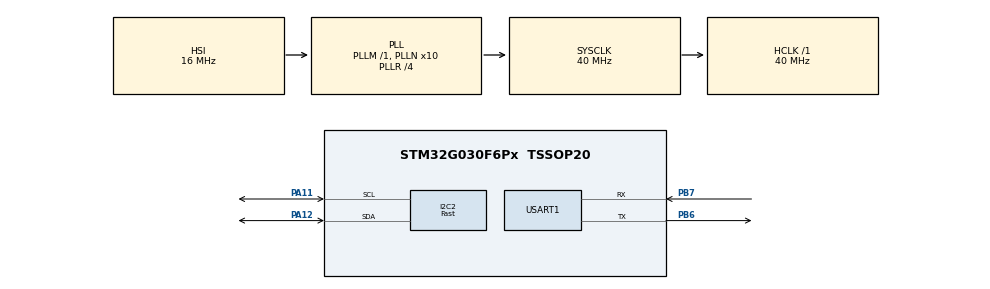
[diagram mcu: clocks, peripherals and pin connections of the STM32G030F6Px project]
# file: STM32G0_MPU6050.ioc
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I2C2.I2C_Speed_Mode=I2C_Fast
I2C2.Timing=0x00301347
Mcu.Family=STM32G0
Mcu.Name=STM32G030F6Px
Mcu.Package=TSSOP20
PA11\ [PA9].Mode=I2C
PA11\ [PA9].Signal=I2C2_SCL
PA12\ [PA10].Mode=I2C
PA12\ [PA10].Signal=I2C2_SDA
PA13.Mode=Serial_Wire
PA13.Signal=SYS_SWDIO
PA14-BOOT0.Mode=Serial_Wire
PA14-BOOT0.Signal=SYS_SWCLK
PA14-BOOT0__PA15.StandardMode=true
PB0__PB1__PB2__PA8.StandardMode=true
PB3__PB4__PB5__PB6.StandardMode=true
PB6.Mode=Asynchronous
PB6.Signal=USART1_TX
PB7.Mode=Asynchronous
PB7.Signal=USART1_RX
PB7__PB8.StandardMode=true
PC14-OSC32_IN\ (PC14)__PB9.StandardMode=true
ProjectManager.HeapSize=0x200
ProjectManager.StackSize=0x400
ProjectManager.TargetToolchain=MDK-ARM V5.32
RCC.ADCFreq_Value=40000000
RCC.AHBFreq_Value=40000000
RCC.CortexFreq_Value=40000000
RCC.EXTERNAL_CLOCK_VALUE=12288000
RCC.HCLKFreq_Value=40000000
RCC.HSE_VALUE=8000000
RCC.HSI_VALUE=16000000
RCC.LSE_VALUE=32768
RCC.PLLN=10
RCC.PLLR=RCC_PLLR_DIV4
RCC.SYSCLKFreq_VALUE=40000000
RCC.SYSCLKSource=RCC_SYSCLKSOURCE_PLLCLK
RCC.VCOOutputFreq_Value=160000000
USART1.VirtualMode-Asynchronous=VM_ASYNC
board=custom

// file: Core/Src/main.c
/* USER CODE BEGIN Header */
/*
 *  supports max 14 channels in this lib (with messagelength of 0x20 there is room for 14 channels)

  Example set of bytes coming over the iBUS line for setting servos:
    20 40 DB 5 DC 5 54 5 DC 5 E8 3 D0 7 D2 5 E8 3 DC 5 DC 5 DC 5 DC 5 DC 5 DC 5 DA F3
  Explanation
    Protocol length: 20
    Command code: 40
    Channel 0: DB 5  -> value 0x5DB
    Channel 1: DC 5  -> value 0x5Dc
    Channel 2: 54 5  -> value 0x554
    Channel 3: DC 5  -> value 0x5DC
    Channel 4: E8 3  -> value 0x3E8
    Channel 5: D0 7  -> value 0x7D0
    Channel 6: D2 5  -> value 0x5D2
    Channel 7: E8 3  -> value 0x3E8
    Channel 8: DC 5  -> value 0x5DC
    Channel 9: DC 5  -> value 0x5DC
    Channel 10: DC 5 -> value 0x5DC
    Channel 11: DC 5 -> value 0x5DC
    Channel 12: DC 5 -> value 0x5DC
    Channel 13: DC 5 -> value 0x5DC
    Checksum: DA F3 -> calculated by adding up all previous bytes, total must be FFFF
*/
/* USER CODE END Header */
#include "main.h"
#include "i2c.h"
#include "usart.h"
#include "gpio.h"

/* USER CODE BEGIN Includes */
#include "mpu6050.h"
/* USER CODE END Includes */

void SystemClock_Config(void);

int main(void)
{

  /* MCU Configuration--------------------------------------------------------*/

  /* Reset of all peripherals, Initializes the Flash interface and the Systick. */
  HAL_Init();

  /* Configure the system clock */
  SystemClock_Config();

  /* Initialize all configured peripherals */
  MX_GPIO_Init();
  MX_USART1_UART_Init();
  MX_I2C2_Init();
  /* USER CODE BEGIN 2 */
  printf("System Begin!\r\n");
  uint8_t addr = 0xff;
  addr = i2c_probe();
  printf("I2C Address: 0x%02x\r\n", addr);//0xD0
  mpu6050_init();
  /* USER CODE END 2 */

  /* Infinite loop */
  while (1)
  {

    /* USER CODE BEGIN 3 */
    uint16_t acc[3];
    mpu6050_read_only_acc(acc);
    printf("Acc: %f %f %f\r\n",
    mpu6050_from_fs2g_to_g(acc[0]),
    mpu6050_from_fs2g_to_g(acc[1]),
    mpu6050_from_fs2g_to_g(acc[2]));
    HAL_Delay(100);
  }
  /* USER CODE END 3 */
}

void SystemClock_Config(void)
{
  RCC_OscInitTypeDef RCC_OscInitStruct = {0};
  RCC_ClkInitTypeDef RCC_ClkInitStruct = {0};

  /** Configure the main internal regulator output voltage
  */
  HAL_PWREx_ControlVoltageScaling(PWR_REGULATOR_VOLTAGE_SCALE1);

  /** Initializes the RCC Oscillators according to the specified parameters
  * in the RCC_OscInitTypeDef structure.
  */
  RCC_OscInitStruct.OscillatorType = RCC_OSCILLATORTYPE_HSI;
  RCC_OscInitStruct.HSIState = RCC_HSI_ON;
  RCC_OscInitStruct.HSIDiv = RCC_HSI_DIV1;
  RCC_OscInitStruct.HSICalibrationValue = RCC_HSICALIBRATION_DEFAULT;
  RCC_OscInitStruct.PLL.PLLState = RCC_PLL_ON;
  RCC_OscInitStruct.PLL.PLLSource = RCC_PLLSOURCE_HSI;
  RCC_OscInitStruct.PLL.PLLM = RCC_PLLM_DIV1;
  RCC_OscInitStruct.PLL.PLLN = 10;
  RCC_OscInitStruct.PLL.PLLP = RCC_PLLP_DIV2;
  RCC_OscInitStruct.PLL.PLLR = RCC_PLLR_DIV4;
  if (HAL_RCC_OscConfig(&RCC_OscInitStruct) != HAL_OK)
  {
    Error_Handler();
  }

  /** Initializes the CPU, AHB and APB buses clocks
  */
  RCC_ClkInitStruct.ClockType = RCC_CLOCKTYPE_HCLK|RCC_CLOCKTYPE_SYSCLK
                              |RCC_CLOCKTYPE_PCLK1;
  RCC_ClkInitStruct.SYSCLKSource = RCC_SYSCLKSOURCE_PLLCLK;
  RCC_ClkInitStruct.AHBCLKDivider = RCC_SYSCLK_DIV1;
  RCC_ClkInitStruct.APB1CLKDivider = RCC_HCLK_DIV1;

  if (HAL_RCC_ClockConfig(&RCC_ClkInitStruct, FLASH_LATENCY_1) != HAL_OK)
  {
    Error_Handler();
  }
}

void Error_Handler(void)
{
  __disable_irq();
  while (1)
  {
  }
}
